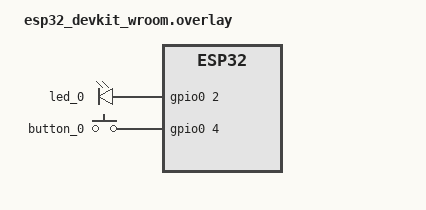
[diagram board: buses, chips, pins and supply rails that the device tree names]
/{
    leds {
        compatible = "gpio-leds";
        led_0:led_0 {
            gpios = <&gpio0 2 GPIO_ACTIVE_HIGH>;
        };
    };

    buttons {
        compatible = "gpio-keys";
        button_0:button_0 {
            gpios = <&gpio0 4 GPIO_ACTIVE_HIGH>;
        };

    };


};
